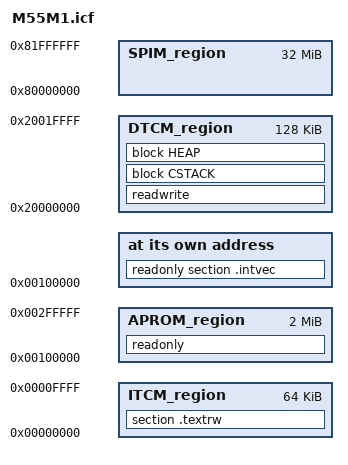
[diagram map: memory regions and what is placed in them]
/*###ICF### Section handled by ICF editor, don't touch! ****/
/*-Editor annotation file-*/
/* IcfEditorFile="$TOOLKIT_DIR$\config\ide\IcfEditor\cortex_v1_0.xml" */
/*-Specials-*/
define symbol __ICFEDIT_intvec_start__ = 0x00100000;
/*-Memory Regions-*/
define symbol __ICFEDIT_region_APROM_start__    = 0x00100000;
define symbol __ICFEDIT_region_APROM_end__      = 0x002FFFFF;
define symbol __ICFEDIT_region_SPIM_start__     = 0x80000000;
define symbol __ICFEDIT_region_SPIM_end__       = 0x81FFFFFF;
define symbol __ICFEDIT_region_ITCM_start__     = 0x00000000;
define symbol __ICFEDIT_region_ITCM_end__       = 0x0000FFFF;
define symbol __ICFEDIT_region_DTCM_start__     = 0x20000000;
define symbol __ICFEDIT_region_DTCM_end__       = 0x2001FFFF;
/*-Sizes-*/
define symbol __ICFEDIT_size_cstack__  = 0xF000;
define symbol __ICFEDIT_size_heap__    = 0x10000;
/**** End of ICF editor section. ###ICF###*/

define memory mem with size = 4G;
define region APROM_region = mem:[from __ICFEDIT_region_APROM_start__ to __ICFEDIT_region_APROM_end__];
define region SPIM_region  = mem:[from __ICFEDIT_region_SPIM_start__ to __ICFEDIT_region_SPIM_end__];
define region ITCM_region  = mem:[from __ICFEDIT_region_ITCM_start__ to __ICFEDIT_region_ITCM_end__];
define region DTCM_region  = mem:[from __ICFEDIT_region_DTCM_start__ to __ICFEDIT_region_DTCM_end__];

define block CSTACK    with alignment = 8, size = __ICFEDIT_size_cstack__   { };
define block HEAP      with alignment = 8, size = __ICFEDIT_size_heap__     { };

initialize by copy { readwrite };
do not initialize  { section .noinit };

place at address mem:__ICFEDIT_intvec_start__ { readonly section .intvec };

place in APROM_region   { readonly };
place in ITCM_region    { section .textrw };
place in DTCM_region    { readwrite, block CSTACK, block HEAP };

export symbol __ICFEDIT_region_ITCM_start__;
export symbol __ICFEDIT_region_ITCM_end__;
export symbol __ICFEDIT_region_DTCM_start__;
export symbol __ICFEDIT_region_DTCM_end__;
